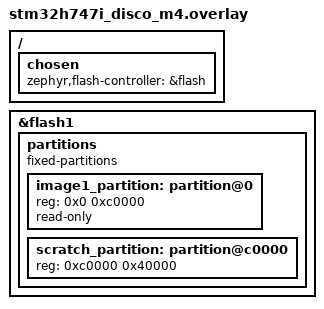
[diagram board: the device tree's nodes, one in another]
/* SPDX-License-Identifier: Apache-2.0 */

/ {
	chosen {
		zephyr,flash-controller = &flash;
	};
};

&flash1 {
	partitions {
		compatible = "fixed-partitions";
			#address-cells = <0x1>;
			#size-cells = <0x1>;
			image1_partition: partition@0 {
				reg = <0x0 0xc0000>;
				read-only;
			};

		/* 256KiB scratch pad */
		scratch_partition: partition@c0000 {
			reg = <0xc0000 0x40000>;
		};
	};
};
